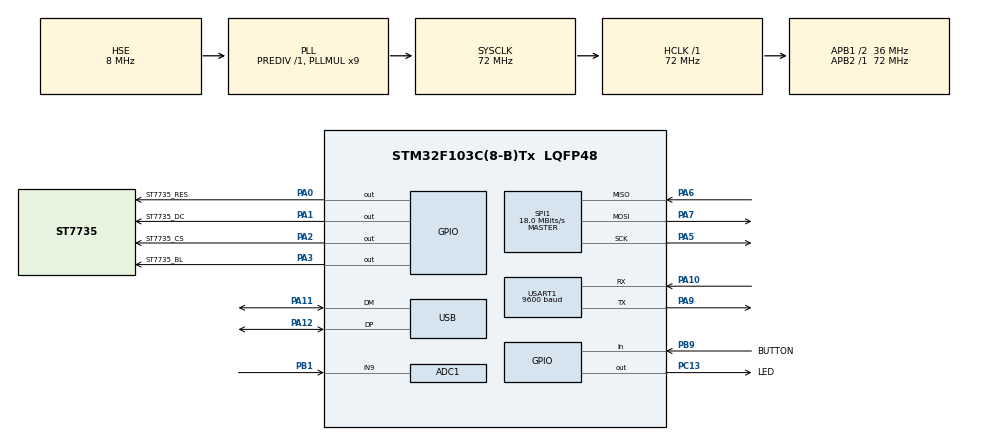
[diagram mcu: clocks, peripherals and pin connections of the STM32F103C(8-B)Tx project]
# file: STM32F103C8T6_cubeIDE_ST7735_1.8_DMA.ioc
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ADC1.Channel-2\#ChannelRegularConversion=ADC_CHANNEL_9
ADC1.NbrOfConversionFlag=1
ADC1.Rank-2\#ChannelRegularConversion=1
ADC1.SamplingTime-2\#ChannelRegularConversion=ADC_SAMPLETIME_1CYCLE_5
ADC1.master=1
Dma.Request0=USART1_RX
Dma.Request1=SPI1_TX
Dma.Request2=USART1_TX
Dma.SPI1_TX.1.Direction=DMA_MEMORY_TO_PERIPH
Dma.SPI1_TX.1.Instance=DMA1_Channel3
Dma.SPI1_TX.1.MemDataAlignment=DMA_MDATAALIGN_BYTE
Dma.SPI1_TX.1.MemInc=DMA_MINC_ENABLE
Dma.SPI1_TX.1.Mode=DMA_NORMAL
Dma.SPI1_TX.1.PeriphDataAlignment=DMA_PDATAALIGN_BYTE
Dma.SPI1_TX.1.PeriphInc=DMA_PINC_DISABLE
Dma.SPI1_TX.1.Priority=DMA_PRIORITY_LOW
Dma.USART1_RX.0.Direction=DMA_PERIPH_TO_MEMORY
Dma.USART1_RX.0.Instance=DMA1_Channel5
Dma.USART1_RX.0.MemDataAlignment=DMA_MDATAALIGN_BYTE
Dma.USART1_RX.0.MemInc=DMA_MINC_ENABLE
Dma.USART1_RX.0.Mode=DMA_NORMAL
Dma.USART1_RX.0.PeriphDataAlignment=DMA_PDATAALIGN_BYTE
Dma.USART1_RX.0.PeriphInc=DMA_PINC_DISABLE
Dma.USART1_RX.0.Priority=DMA_PRIORITY_LOW
Dma.USART1_TX.2.Direction=DMA_MEMORY_TO_PERIPH
Dma.USART1_TX.2.Instance=DMA1_Channel4
Dma.USART1_TX.2.MemDataAlignment=DMA_MDATAALIGN_BYTE
Dma.USART1_TX.2.MemInc=DMA_MINC_ENABLE
Dma.USART1_TX.2.Mode=DMA_NORMAL
Dma.USART1_TX.2.PeriphDataAlignment=DMA_PDATAALIGN_BYTE
Dma.USART1_TX.2.PeriphInc=DMA_PINC_DISABLE
Dma.USART1_TX.2.Priority=DMA_PRIORITY_LOW
IWDG.Prescaler=IWDG_PRESCALER_4
Mcu.Family=STM32F1
Mcu.Name=STM32F103C(8-B)Tx
Mcu.Package=LQFP48
NVIC.DMA1_Channel3_IRQn=true\:0\:0\:false\:false\:true\:false\:true
NVIC.DMA1_Channel4_IRQn=true\:0\:0\:false\:false\:true\:false\:true
NVIC.DMA1_Channel5_IRQn=true\:0\:0\:false\:false\:true\:false\:true
NVIC.PriorityGroup=NVIC_PRIORITYGROUP_4
NVIC.TIM4_IRQn=true\:0\:0\:false\:false\:true\:false\:true
NVIC.TimeBase=TIM4_IRQn
NVIC.TimeBaseIP=TIM4
NVIC.USART1_IRQn=true\:0\:0\:false\:false\:true\:true\:true
NVIC.USB_LP_CAN1_RX0_IRQn=true\:0\:0\:false\:false\:true\:true\:true
PA0-WKUP.GPIO_Label=ST7735_RES
PA0-WKUP.GPIO_Speed=GPIO_SPEED_FREQ_LOW
PA0-WKUP.Signal=GPIO_Output
PA1.GPIO_Label=ST7735_DC
PA1.Signal=GPIO_Output
PA10.Mode=Asynchronous
PA10.Signal=USART1_RX
PA11.Mode=Device
PA11.Signal=USB_DM
PA12.Mode=Device
PA12.Signal=USB_DP
PA13.Mode=Serial_Wire
PA13.Signal=SYS_JTMS-SWDIO
PA14.Mode=Serial_Wire
PA14.Signal=SYS_JTCK-SWCLK
PA2.GPIO_Label=ST7735_CS
PA2.Signal=GPIO_Output
PA3.GPIO_Label=ST7735_BL
PA3.Signal=GPIO_Output
PA5.Mode=Full_Duplex_Master
PA5.Signal=SPI1_SCK
PA6.Mode=Full_Duplex_Master
PA6.Signal=SPI1_MISO
PA7.Mode=Full_Duplex_Master
PA7.Signal=SPI1_MOSI
PA9.Mode=Asynchronous
PA9.Signal=USART1_TX
PB1.Signal=ADCx_IN9
PB9.GPIO_Label=BUTTON
PB9.GPIO_PuPd=GPIO_PULLUP
PB9.Signal=GPIO_Input
PC13-TAMPER-RTC.GPIO_Label=LED
PC13-TAMPER-RTC.Signal=GPIO_Output
PD0-OSC_IN.Mode=HSE-External-Oscillator
PD0-OSC_IN.Signal=RCC_OSC_IN
PD1-OSC_OUT.Mode=HSE-External-Oscillator
PD1-OSC_OUT.Signal=RCC_OSC_OUT
ProjectManager.HeapSize=0x200
ProjectManager.StackSize=0x400
ProjectManager.TargetToolchain=STM32CubeIDE
RCC.ADCPresc=RCC_ADCPCLK2_DIV6
RCC.AHBFreq_Value=72000000
RCC.APB1CLKDivider=RCC_HCLK_DIV2
RCC.APB1Freq_Value=36000000
RCC.APB1TimFreq_Value=72000000
RCC.APB2Freq_Value=72000000
RCC.APB2TimFreq_Value=72000000
RCC.HCLKFreq_Value=72000000
RCC.PLLMUL=RCC_PLL_MUL9
RCC.PLLSourceVirtual=RCC_PLLSOURCE_HSE
RCC.SYSCLKFreq_VALUE=72000000
RCC.SYSCLKSource=RCC_SYSCLKSOURCE_PLLCLK
RCC.USBFreq_Value=48000000
RCC.USBPrescaler=RCC_USBCLKSOURCE_PLL_DIV1_5
SH.ADCx_IN9.0=ADC1_IN9,IN9
SPI1.BaudRatePrescaler=SPI_BAUDRATEPRESCALER_4
SPI1.CRCCalculation=SPI_CRCCALCULATION_DISABLE
SPI1.CalculateBaudRate=18.0 MBits/s
SPI1.Direction=SPI_DIRECTION_2LINES
SPI1.Mode=SPI_MODE_MASTER
SPI1.VirtualType=VM_MASTER
USART1.BaudRate=9600
USART1.Mode=MODE_TX_RX
USART1.VirtualMode=VM_ASYNC
USB_DEVICE.CLASS_NAME_FS=CDC
USB_DEVICE.VirtualMode=Cdc
USB_DEVICE.VirtualModeFS=Cdc_FS
VP_CRC_VS_CRC.Mode=CRC_Activate
VP_IWDG_VS_IWDG.Mode=IWDG_Activate
VP_SYS_VS_tim4.Mode=TIM4
VP_TIM3_VS_ClockSourceINT.Mode=Internal
VP_USB_DEVICE_VS_USB_DEVICE_CDC_FS.Mode=CDC_FS
board=custom

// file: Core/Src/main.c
/* USER CODE BEGIN Header */
/**
  ******************************************************************************
  * @file           : main.c
  * @brief          : Main program body
  ******************************************************************************
  * @attention
  *
  * <h2><center>&copy; Copyright (c) 2019 STMicroelectronics.
  * All rights reserved.</center></h2>
  *
  * This software component is licensed by ST under BSD 3-Clause license,
  * the "License"; You may not use this file except in compliance with the
  * License. You may obtain a copy of the License at:
  *                        opensource.org/licenses/BSD-3-Clause
  *
  ******************************************************************************
  */
/* USER CODE END Header */

#include "main.h"
#include "usb_device.h"

/* USER CODE BEGIN Includes */

#include "st7735.h"
#include "mc6000.h"

/* USER CODE END Includes */

ADC_HandleTypeDef hadc1;

CRC_HandleTypeDef hcrc;

IWDG_HandleTypeDef hiwdg;

SPI_HandleTypeDef hspi1;
DMA_HandleTypeDef hdma_spi1_tx;

TIM_HandleTypeDef htim3;

UART_HandleTypeDef huart1;
DMA_HandleTypeDef hdma_usart1_rx;
DMA_HandleTypeDef hdma_usart1_tx;

void SystemClock_Config(void);
static void MX_GPIO_Init(void);
static void MX_DMA_Init(void);
static void MX_SPI1_Init(void);
static void MX_USART1_UART_Init(void);
static void MX_TIM3_Init(void);
static void MX_ADC1_Init(void);
static void MX_CRC_Init(void);
static void MX_IWDG_Init(void);

int main(void)
{

  /* MCU Configuration--------------------------------------------------------*/

  /* Reset of all peripherals, Initializes the Flash interface and the Systick. */
  HAL_Init();

  /* Configure the system clock */
  SystemClock_Config();

  /* Initialize all configured peripherals */
  MX_GPIO_Init();
  MX_DMA_Init();
  MX_SPI1_Init();
  MX_USART1_UART_Init();
  MX_TIM3_Init();
  MX_ADC1_Init();
  MX_CRC_Init();
  MX_USB_DEVICE_Init();
  MX_IWDG_Init();
  /* USER CODE BEGIN 2 */
  ST7735_Init();
  ST7735_Backlight_On();

  ST7735_SetRotation(0);
  ST7735_FillScreen(ST7735_BLACK);
  HAL_IWDG_Init(&hiwdg);

  /* USER CODE END 2 */

  /* Infinite loop */
  /* USER CODE BEGIN WHILE */
  while (1)
  {
//	  demoTFT();
	  readUART();
	  printBuffer();
	  writeUART();
	  checkButton();
    /* USER CODE END WHILE */

  }
}

void SystemClock_Config(void)
{
  RCC_OscInitTypeDef RCC_OscInitStruct = {0};
  RCC_ClkInitTypeDef RCC_ClkInitStruct = {0};
  RCC_PeriphCLKInitTypeDef PeriphClkInit = {0};

  /** Initializes the CPU, AHB and APB busses clocks
  */
  RCC_OscInitStruct.OscillatorType = RCC_OSCILLATORTYPE_LSI|RCC_OSCILLATORTYPE_HSE;
  RCC_OscInitStruct.HSEState = RCC_HSE_ON;
  RCC_OscInitStruct.HSEPredivValue = RCC_HSE_PREDIV_DIV1;
  RCC_OscInitStruct.HSIState = RCC_HSI_ON;
  RCC_OscInitStruct.LSIState = RCC_LSI_ON;
  RCC_OscInitStruct.PLL.PLLState = RCC_PLL_ON;
  RCC_OscInitStruct.PLL.PLLSource = RCC_PLLSOURCE_HSE;
  RCC_OscInitStruct.PLL.PLLMUL = RCC_PLL_MUL9;
  if (HAL_RCC_OscConfig(&RCC_OscInitStruct) != HAL_OK)
  {
    Error_Handler();
  }
  /** Initializes the CPU, AHB and APB busses clocks
  */
  RCC_ClkInitStruct.ClockType = RCC_CLOCKTYPE_HCLK|RCC_CLOCKTYPE_SYSCLK
                              |RCC_CLOCKTYPE_PCLK1|RCC_CLOCKTYPE_PCLK2;
  RCC_ClkInitStruct.SYSCLKSource = RCC_SYSCLKSOURCE_PLLCLK;
  RCC_ClkInitStruct.AHBCLKDivider = RCC_SYSCLK_DIV1;
  RCC_ClkInitStruct.APB1CLKDivider = RCC_HCLK_DIV2;
  RCC_ClkInitStruct.APB2CLKDivider = RCC_HCLK_DIV1;

  if (HAL_RCC_ClockConfig(&RCC_ClkInitStruct, FLASH_LATENCY_2) != HAL_OK)
  {
    Error_Handler();
  }
  PeriphClkInit.PeriphClockSelection = RCC_PERIPHCLK_ADC|RCC_PERIPHCLK_USB;
  PeriphClkInit.AdcClockSelection = RCC_ADCPCLK2_DIV6;
  PeriphClkInit.UsbClockSelection = RCC_USBCLKSOURCE_PLL_DIV1_5;
  if (HAL_RCCEx_PeriphCLKConfig(&PeriphClkInit) != HAL_OK)
  {
    Error_Handler();
  }
}

static void MX_ADC1_Init(void)
{

  ADC_ChannelConfTypeDef sConfig = {0};

  /** Common config
  */
  hadc1.Instance = ADC1;
  hadc1.Init.ScanConvMode = ADC_SCAN_DISABLE;
  hadc1.Init.ContinuousConvMode = DISABLE;
  hadc1.Init.DiscontinuousConvMode = DISABLE;
  hadc1.Init.ExternalTrigConv = ADC_SOFTWARE_START;
  hadc1.Init.DataAlign = ADC_DATAALIGN_RIGHT;
  hadc1.Init.NbrOfConversion = 1;
  if (HAL_ADC_Init(&hadc1) != HAL_OK)
  {
    Error_Handler();
  }
  /** Configure Regular Channel
  */
  sConfig.Channel = ADC_CHANNEL_9;
  sConfig.Rank = ADC_REGULAR_RANK_1;
  sConfig.SamplingTime = ADC_SAMPLETIME_1CYCLE_5;
  if (HAL_ADC_ConfigChannel(&hadc1, &sConfig) != HAL_OK)
  {
    Error_Handler();
  }

}

static void MX_CRC_Init(void)
{

  hcrc.Instance = CRC;
  if (HAL_CRC_Init(&hcrc) != HAL_OK)
  {
    Error_Handler();
  }

}

static void MX_IWDG_Init(void)
{

  hiwdg.Instance = IWDG;
  hiwdg.Init.Prescaler = IWDG_PRESCALER_4;
  hiwdg.Init.Reload = 4095;
  if (HAL_IWDG_Init(&hiwdg) != HAL_OK)
  {
    Error_Handler();
  }

}

static void MX_SPI1_Init(void)
{

  /* SPI1 parameter configuration*/
  hspi1.Instance = SPI1;
  hspi1.Init.Mode = SPI_MODE_MASTER;
  hspi1.Init.Direction = SPI_DIRECTION_2LINES;
  hspi1.Init.DataSize = SPI_DATASIZE_8BIT;
  hspi1.Init.CLKPolarity = SPI_POLARITY_LOW;
  hspi1.Init.CLKPhase = SPI_PHASE_1EDGE;
  hspi1.Init.NSS = SPI_NSS_SOFT;
  hspi1.Init.BaudRatePrescaler = SPI_BAUDRATEPRESCALER_4;
  hspi1.Init.FirstBit = SPI_FIRSTBIT_MSB;
  hspi1.Init.TIMode = SPI_TIMODE_DISABLE;
  hspi1.Init.CRCCalculation = SPI_CRCCALCULATION_DISABLE;
  hspi1.Init.CRCPolynomial = 10;
  if (HAL_SPI_Init(&hspi1) != HAL_OK)
  {
    Error_Handler();
  }

}

static void MX_TIM3_Init(void)
{

  TIM_ClockConfigTypeDef sClockSourceConfig = {0};
  TIM_MasterConfigTypeDef sMasterConfig = {0};

  htim3.Instance = TIM3;
  htim3.Init.Prescaler = 0;
  htim3.Init.CounterMode = TIM_COUNTERMODE_UP;
  htim3.Init.Period = 0;
  htim3.Init.ClockDivision = TIM_CLOCKDIVISION_DIV1;
  htim3.Init.AutoReloadPreload = TIM_AUTORELOAD_PRELOAD_DISABLE;
  if (HAL_TIM_Base_Init(&htim3) != HAL_OK)
  {
    Error_Handler();
  }
  sClockSourceConfig.ClockSource = TIM_CLOCKSOURCE_INTERNAL;
  if (HAL_TIM_ConfigClockSource(&htim3, &sClockSourceConfig) != HAL_OK)
  {
    Error_Handler();
  }
  sMasterConfig.MasterOutputTrigger = TIM_TRGO_RESET;
  sMasterConfig.MasterSlaveMode = TIM_MASTERSLAVEMODE_DISABLE;
  if (HAL_TIMEx_MasterConfigSynchronization(&htim3, &sMasterConfig) != HAL_OK)
  {
    Error_Handler();
  }

}

static void MX_USART1_UART_Init(void)
{

  huart1.Instance = USART1;
  huart1.Init.BaudRate = 9600;
  huart1.Init.WordLength = UART_WORDLENGTH_8B;
  huart1.Init.StopBits = UART_STOPBITS_1;
  huart1.Init.Parity = UART_PARITY_NONE;
  huart1.Init.Mode = UART_MODE_TX_RX;
  huart1.Init.HwFlowCtl = UART_HWCONTROL_NONE;
  huart1.Init.OverSampling = UART_OVERSAMPLING_16;
  if (HAL_UART_Init(&huart1) != HAL_OK)
  {
    Error_Handler();
  }

}

static void MX_DMA_Init(void)
{

  /* DMA controller clock enable */
  __HAL_RCC_DMA1_CLK_ENABLE();

  /* DMA interrupt init */
  /* DMA1_Channel3_IRQn interrupt configuration */
  HAL_NVIC_SetPriority(DMA1_Channel3_IRQn, 0, 0);
  HAL_NVIC_EnableIRQ(DMA1_Channel3_IRQn);
  /* DMA1_Channel4_IRQn interrupt configuration */
  HAL_NVIC_SetPriority(DMA1_Channel4_IRQn, 0, 0);
  HAL_NVIC_EnableIRQ(DMA1_Channel4_IRQn);
  /* DMA1_Channel5_IRQn interrupt configuration */
  HAL_NVIC_SetPriority(DMA1_Channel5_IRQn, 0, 0);
  HAL_NVIC_EnableIRQ(DMA1_Channel5_IRQn);

}

static void MX_GPIO_Init(void)
{
  GPIO_InitTypeDef GPIO_InitStruct = {0};

  /* GPIO Ports Clock Enable */
  __HAL_RCC_GPIOC_CLK_ENABLE();
  __HAL_RCC_GPIOD_CLK_ENABLE();
  __HAL_RCC_GPIOA_CLK_ENABLE();
  __HAL_RCC_GPIOB_CLK_ENABLE();

  /*Configure GPIO pin Output Level */
  HAL_GPIO_WritePin(LED_GPIO_Port, LED_Pin, GPIO_PIN_RESET);

  /*Configure GPIO pin Output Level */
  HAL_GPIO_WritePin(GPIOA, ST7735_RES_Pin|ST7735_DC_Pin|ST7735_CS_Pin|ST7735_BL_Pin, GPIO_PIN_RESET);

  /*Configure GPIO pin : LED_Pin */
  GPIO_InitStruct.Pin = LED_Pin;
  GPIO_InitStruct.Mode = GPIO_MODE_OUTPUT_PP;
  GPIO_InitStruct.Pull = GPIO_NOPULL;
  GPIO_InitStruct.Speed = GPIO_SPEED_FREQ_LOW;
  HAL_GPIO_Init(LED_GPIO_Port, &GPIO_InitStruct);

  /*Configure GPIO pins : ST7735_RES_Pin ST7735_DC_Pin ST7735_CS_Pin ST7735_BL_Pin */
  GPIO_InitStruct.Pin = ST7735_RES_Pin|ST7735_DC_Pin|ST7735_CS_Pin|ST7735_BL_Pin;
  GPIO_InitStruct.Mode = GPIO_MODE_OUTPUT_PP;
  GPIO_InitStruct.Pull = GPIO_NOPULL;
  GPIO_InitStruct.Speed = GPIO_SPEED_FREQ_LOW;
  HAL_GPIO_Init(GPIOA, &GPIO_InitStruct);

  /*Configure GPIO pin : BUTTON_Pin */
  GPIO_InitStruct.Pin = BUTTON_Pin;
  GPIO_InitStruct.Mode = GPIO_MODE_INPUT;
  GPIO_InitStruct.Pull = GPIO_PULLUP;
  HAL_GPIO_Init(BUTTON_GPIO_Port, &GPIO_InitStruct);

}

 /**
  * @brief  Period elapsed callback in non blocking mode
  * @note   This function is called  when TIM4 interrupt took place, inside
  * HAL_TIM_IRQHandler(). It makes a direct call to HAL_IncTick() to increment
  * a global variable "uwTick" used as application time base.
  * @param  htim : TIM handle
  * @retval None
  */
void HAL_TIM_PeriodElapsedCallback(TIM_HandleTypeDef *htim)
{
  if (htim->Instance == TIM4) {
    HAL_IncTick();
  }
}

void Error_Handler(void)
{
}

/************************ (C) COPYRIGHT STMicroelectronics *****END OF FILE****/
